# ATSAM4SP32A register map
Vendor: Atmel; File version: 0
CPU: CM4 r0p1, selectable endian, no MPU, no FPU, 0x4 interrupt priority bits, 0x0 interrupts
Registers are 32-bit, read-write, reset 0x0 unless marked. A register's access mark holds for its fields unless they carry their own. Offsets are from the block's base; [hi:lo] are bit positions; {n}, {i} and the like mark numbered series.

## CRCCU — Cyclic Redundancy Check Calculation Unit
Base 0x40044000; register names take the prefix CRCCU_
0x00 DSCR — CRCCU Descriptor Base Register
  [31:9] DSCR — Descriptor Base Address
0x08 DMA_EN wo — CRCCU DMA Enable Register
  [0] DMAEN — DMA Enable Register
0x0C DMA_DIS wo — CRCCU DMA Disable Register
  [0] DMADIS — DMA Disable Register
0x10 DMA_SR ro — CRCCU DMA Status Register
  [0] DMASR — DMA Status Register
0x14 DMA_IER wo — CRCCU DMA Interrupt Enable Register
  [0] DMAIER — Interrupt Enable register
0x18 DMA_IDR wo — CRCCU DMA Interrupt Disable Register
  [0] DMAIDR — Interrupt Disable register
0x1C DMA_IMR ro — CRCCU DMA Interrupt Mask Register
  [0] DMAIMR — Interrupt Mask Register
0x20 DMA_ISR ro — CRCCU DMA Interrupt Status Register
  [0] DMAISR — Interrupt Status register
0x34 CR wo — CRCCU Control Register
  [0] RESET — CRC Computation Reset
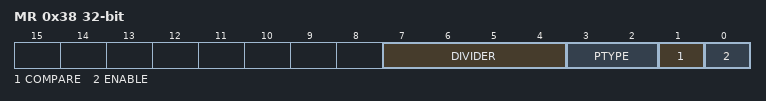
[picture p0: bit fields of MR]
0x38 MR — CRCCU Mode Register
  [7:4] DIVIDER — Request Divider
  [3:2] PTYPE — Primitive Polynomial
    0=CCITT8023 (Polynom 0x04C11DB7); 1=CASTAGNOLI (Polynom 0x1EDC6F41); 2=CCITT16 (Polynom 0x1021)
  [1] COMPARE — CRC Compare
  [0] ENABLE — CRC Enable
0x3C SR ro reset 0xFFFFFFFF — CRCCU Status Register
  [31:0] CRC — Cyclic Redundancy Check Value
0x40 IER wo — CRCCU Interrupt Enable Register
  [0] ERRIER — CRC Error Interrupt Enable
0x44 IDR wo — CRCCU Interrupt Disable Register
  [0] ERRIDR — CRC Error Interrupt Disable
0x48 IMR ro — CRCCU Interrupt Mask Register
  [0] ERRIMR — CRC Error Interrupt Mask
0x4C ISR ro — CRCCU Interrupt Status Register
  [0] ERRISR — CRC Error Interrupt Status

## CMCC — Cortex M Cache Controller
Base 0x4007C000; register names take the prefix CMCC_
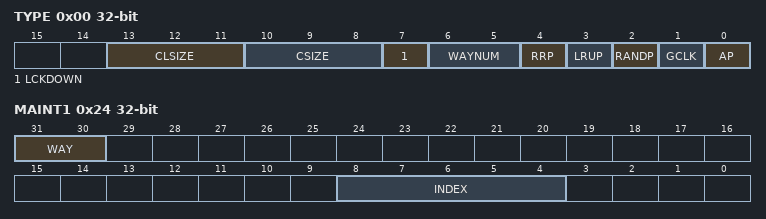
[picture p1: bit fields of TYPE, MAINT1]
0x00 TYPE ro reset not defined — Cache Type Register
  [13:11] CLSIZE — Cache Size
    0=CLSIZE_1KB (4 bytes); 1=CLSIZE_2KB (8 bytes); 2=CLSIZE_4KB (16 bytes); 3=CLSIZE_8KB (32 bytes)
  [10:8] CSIZE — Cache Size
    0=CSIZE_1KB (Cache Size 1 Kbytes); 1=CSIZE_2KB (Cache Size 2 Kbytes); 2=CSIZE_4KB (Cache Size 4 Kbytes); 3=CSIZE_8KB (Cache Size 8 Kbytes)
  [7] LCKDOWN — Lock Down Supported
  [6:5] WAYNUM — Number of Way
    0=DMAPPED (Direct Mapped Cache); 1=ARCH2WAY (2-WAY set associative); 2=ARCH4WAY (4-WAY set associative); 3=ARCH8WAY (8-WAY set associative)
  [4] RRP — Random Selection Policy Supported
  [3] LRUP — Least Recently Used Policy Supported
  [2] RANDP — Random Selection Policy Supported
  [1] GCLK — Dynamic Clock Gating Supported
  [0] AP — Access Port Access Allowed
0x04 CFG — Cache Configuration Register
  [0] GCLKDIS — Disable Clock Gating
0x08 CTRL wo — Cache Control Register
  [0] CEN — Cache Controller Enable
0x0C SR ro — Cache Status Register
  [0] CSTS — Cache Controller Status
0x20 MAINT0 wo reset not defined — Cache Maintenance Register 0
  [0] INVALL — Cache Controller Invalidate All
0x24 MAINT1 wo reset not defined — Cache Maintenance Register 1
  [31:30] WAY — Invalidate Way
    {v}=Way {v} is selection for index invalidation (v=0..3)
  [8:4] INDEX — Invalidate Index
0x28 MCFG — Cache Monitor Configuration Register
  [1:0] MODE — Cache Controller Monitor Counter Mode
    0=CYCLE_COUNT (Cycle counter); 1=IHIT_COUNT (Instruction hit counter); 2=DHIT_COUNT (Data hit counter)
0x2C MEN — Cache Monitor Enable Register
  [0] MENABLE — Cache Controller Monitor Enable
0x30 MCTRL wo reset not defined — Cache Monitor Control Register
  [0] SWRST — Monitor
0x34 MSR ro — Cache Monitor Status Register
  [31:0] EVENT_CNT — Monitor Event Counter

## MATRIX — AHB Bus Matrix
Base 0x400E0200
{0x0+4i} MATRIX_MCFG[{i}] reset not defined (i=0..3) — Master Configuration Register
  [2:0] ULBT — Undefined Length Burst Type
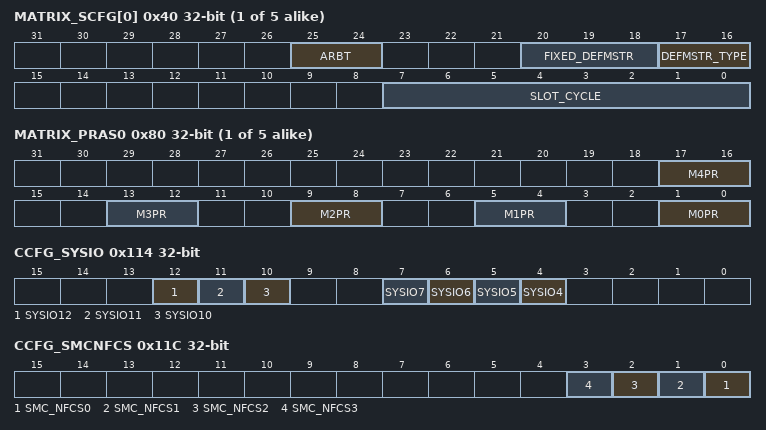
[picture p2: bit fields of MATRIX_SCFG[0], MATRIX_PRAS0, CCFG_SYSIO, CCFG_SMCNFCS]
{0x40+4i} MATRIX_SCFG[{i}] reset not defined (i=0..4) — Slave Configuration Register
  [25:24] ARBT — Arbitration Type
  [20:18] FIXED_DEFMSTR — Fixed Default Master
  [17:16] DEFMSTR_TYPE — Default Master Type
  [7:0] SLOT_CYCLE — Maximum Number of Allowed Cycles for a Burst
{0x80+8i} MATRIX_PRAS{i} (i=0..4) — Priority Register A for Slave {i}
  [4n+1:4n] M{n}PR (n=0..4) — Master {n} Priority
0x114 CCFG_SYSIO — System I/O Configuration register
  [12] SYSIO12 — PB12 or ERASE Assignment
  [11] SYSIO11 — PB11 or DDP Assignment
  [10] SYSIO10 — PB10 or DDM Assignment
  [7] SYSIO7 — PB7 or TCK/SWCLK Assignment
  [6] SYSIO6 — PB6 or TMS/SWDIO Assignment
  [5] SYSIO5 — PB5 or TDO/TRACESWO Assignment
  [4] SYSIO4 — PB4 or TDI Assignment
0x11C CCFG_SMCNFCS — SMC Chip Select NAND Flash Assignment Register
  [n] SMC_NFCS{n} (n=0..3) — SMC NAND Flash Chip Select {n} Assignment
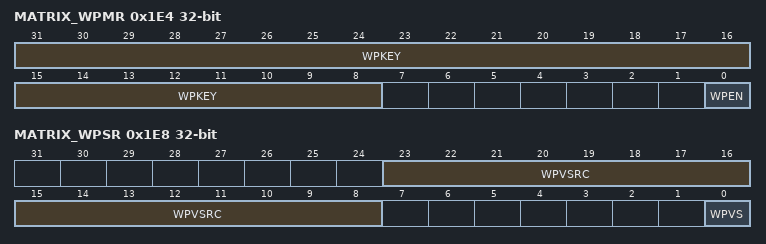
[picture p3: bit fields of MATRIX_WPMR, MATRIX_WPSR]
0x1E4 MATRIX_WPMR — Write Protect Mode Register
  [31:8] WPKEY — Write Protect KEY (Write-only)
  [0] WPEN — Write Protect ENable
0x1E8 MATRIX_WPSR ro — Write Protect Status Register
  [23:8] WPVSRC — Write Protect Violation Source
  [0] WPVS — Write Protect Violation Status
